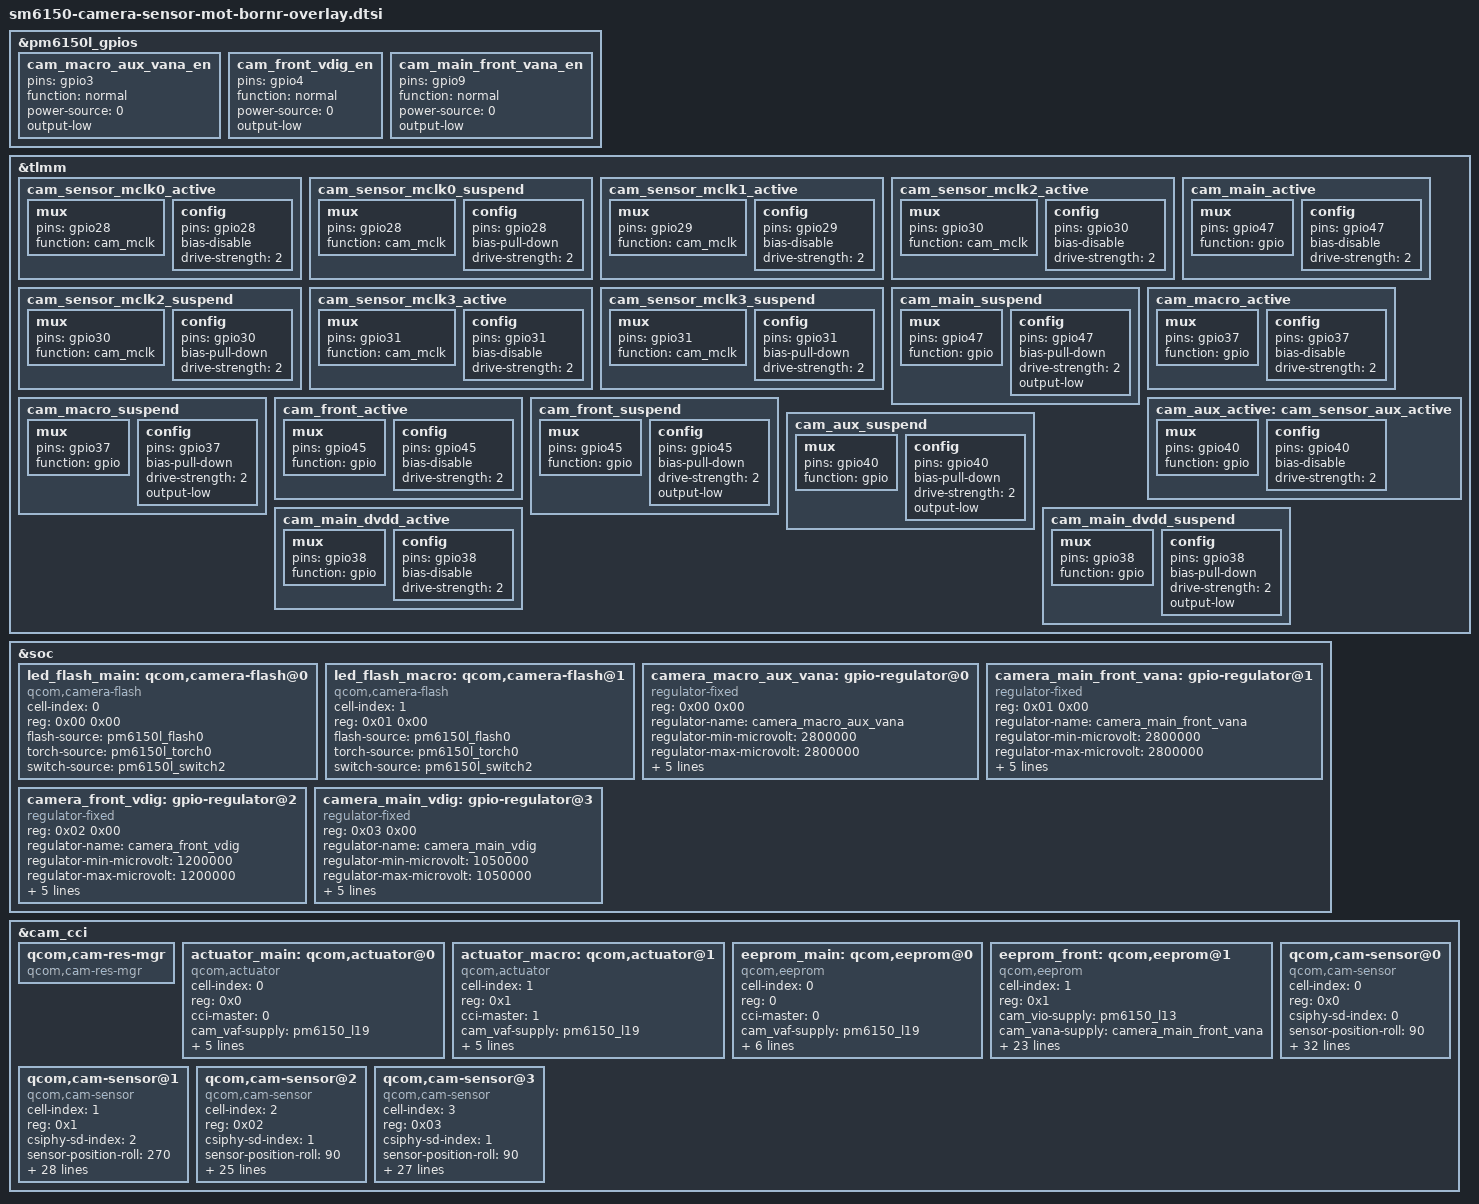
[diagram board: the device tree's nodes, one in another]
/*
 * Copyright (c) 2020, The Linux Foundation. All rights reserved.
 *
 * This program is free software; you can redistribute it and/or modify
 * it under the terms of the GNU General Public License version 2 and
 * only version 2 as published by the Free Software Foundation.
 *
 * This program is distributed in the hope that it will be useful,
 * but WITHOUT ANY WARRANTY; without even the implied warranty of
 * MERCHANTABILITY or FITNESS FOR A PARTICULAR PURPOSE.  See the
 * GNU General Public License for more details.
 */
&pm6150l_gpios {
	cam_macro_aux_vana_en: cam_macro_aux_vana_en {
		pins = "gpio3";
		function = "normal";
		power-source = <0>;
		output-low;
	};
	cam_front_vdig_en: cam_front_vdig_en {
		pins = "gpio4";
		function = "normal";
		power-source = <0>;
		output-low;
	};
	cam_main_front_vana_en: cam_main_front_vana_en {
		pins = "gpio9";
		function = "normal";
		power-source = <0>;
		output-low;
	};
};

&tlmm {
	cam_sensor_mclk0_active: cam_sensor_mclk0_active {
		/* MCLK0 */
		mux {
			pins = "gpio28";
			function = "cam_mclk";
		};

		config {
			pins = "gpio28";
			bias-disable; /* No PULL */
			drive-strength = <2>; /* 2 MA */
		};
	};

	cam_sensor_mclk0_suspend: cam_sensor_mclk0_suspend {
		/* MCLK0 */
		mux {
			pins = "gpio28";
			function = "cam_mclk";
		};

		config {
			pins = "gpio28";
			bias-pull-down; /* PULL DOWN */
			drive-strength = <2>; /* 2 MA */
		};
	};

	cam_sensor_mclk1_active: cam_sensor_mclk1_active {
		/* MCLK1 */
		mux {
			pins = "gpio29";
			function = "cam_mclk";
		};

		config {
			pins = "gpio29";
			bias-disable; /* No PULL */
			drive-strength = <2>; /* 2 MA */
		};
	};

	cam_sensor_mclk2_active: cam_sensor_mclk2_active {
		/* MCLK2 */
		mux {
			pins = "gpio30";
			function = "cam_mclk";
		};

		config {
			pins = "gpio30";
			bias-disable; /* No PULL */
			drive-strength = <2>; /* 2 MA */
		};
	};

	cam_sensor_mclk2_suspend: cam_sensor_mclk2_suspend {
		/* MCLK2 */
		mux {
			pins = "gpio30";
			function = "cam_mclk";
		};

		config {
			pins = "gpio30";
			bias-pull-down; /* PULL DOWN */
			drive-strength = <2>; /* 2 MA */
		};
	};

	cam_sensor_mclk3_active: cam_sensor_mclk3_active {
		/* MCLK3 */
		mux {
			pins = "gpio31";
			function = "cam_mclk";
		};

		config {
			pins = "gpio31";
			bias-disable; /* No PULL */
			drive-strength = <2>; /* 2 MA */
		};
	};

	cam_sensor_mclk3_suspend: cam_sensor_mclk3_suspend {
		/* MCLK3 */
		mux {
			pins = "gpio31";
			function = "cam_mclk";
		};

		config {
			pins = "gpio31";
			bias-pull-down; /* PULL DOWN */
			drive-strength = <2>; /* 2 MA */
		};
	};

	cam_main_active: cam_main_active {
		/* MAIN RESET */
		mux {
			pins = "gpio47";
			function = "gpio";
		};

		config {
			pins = "gpio47";
			bias-disable; /* No PULL */
			drive-strength = <2>; /* 2 MA */
		};
	};

	cam_main_suspend: cam_main_suspend {
		/* MAIN RESET */
		mux {
			pins = "gpio47";
			function = "gpio";
		};

		config {
			pins = "gpio47";
			bias-pull-down; /* PULL DOWN */
			drive-strength = <2>; /* 2 MA */
			output-low;
		};
	};

	cam_macro_active: cam_macro_active {
		/* MACRO RESET  */
		mux {
			pins = "gpio37";
			function = "gpio";
		};

		config {
			pins = "gpio37";
			bias-disable; /* No PULL */
			drive-strength = <2>; /* 2 MA */
		};
	};

	cam_macro_suspend: cam_macro_suspend {
		/* MACRO RESET */
		mux {
			pins = "gpio37";
			function = "gpio";
		};

		config {
			pins = "gpio37";
			bias-pull-down; /* PULL DOWN */
			drive-strength = <2>; /* 2 MA */
			output-low;
		};
	};

	cam_front_active: cam_front_active {
		/* FRONT RESET */
		mux {
			pins = "gpio45";
			function = "gpio";
		};

		config {
			pins = "gpio45";
			bias-disable; /* No PULL */
			drive-strength = <2>; /* 2 MA */
		};
	};

	cam_front_suspend: cam_front_suspend {
		/* FRONT RESET */
		mux {
			pins = "gpio45";
			function = "gpio";
		};

		config {
			pins = "gpio45";
			bias-pull-down; /* PULL DOWN */
			drive-strength = <2>; /* 2 MA */
			output-low;
		};
	};

	cam_aux_active: cam_sensor_aux_active {
		/* DEPTH RESET */
		mux {
			pins = "gpio40";
			function = "gpio";
		};

		config {
			pins = "gpio40";
			bias-disable; /* No PULL */
			drive-strength = <2>; /* 2 MA */
		};
	};

	cam_aux_suspend: cam_aux_suspend {
		/* DEPTH RESET */
		mux {
			pins = "gpio40";
			function = "gpio";
		};

		config {
			pins = "gpio40";
			bias-pull-down; /* PULL DOWN */
			drive-strength = <2>; /* 2 MA */
			output-low;
		};
	};

	cam_main_dvdd_active: cam_main_dvdd_active {
		/* MAIN DVDD EN */
		mux {
			pins = "gpio38";
			function = "gpio";
		};

		config {
			pins = "gpio38";
			bias-disable; /* No PULL */
			drive-strength = <2>; /* 2 MA */
		};
	};

	cam_main_dvdd_suspend: cam_main_dvdd_suspend {
		/* MAIN DVDD EN */
		mux {
			pins = "gpio38";
			function = "gpio";
		};

		config {
			pins = "gpio38";
			bias-pull-down; /* PULL DOWN */
			drive-strength = <2>; /* 2 MA */
			output-low;
		};
	};
};

&soc {

	led_flash_main: qcom,camera-flash@0 {
		cell-index = <0>;
		reg = <0x00 0x00>;
		compatible = "qcom,camera-flash";
		flash-source = <&pm6150l_flash0>;
		torch-source = <&pm6150l_torch0>;
		switch-source = <&pm6150l_switch2>;
		status = "ok";
	};

	led_flash_macro: qcom,camera-flash@1 {
		cell-index = <1>;
		reg = <0x01 0x00>;
		compatible = "qcom,camera-flash";
		flash-source = <&pm6150l_flash0>;
		torch-source = <&pm6150l_torch0>;
		switch-source = <&pm6150l_switch2>;
		status = "ok";
	};

	camera_macro_aux_vana: gpio-regulator@0 {
		compatible = "regulator-fixed";
		reg = <0x00 0x00>;
		regulator-name = "camera_macro_aux_vana";
		regulator-min-microvolt = <2800000>;
		regulator-max-microvolt = <2800000>;
		regulator-enable-ramp-delay = <135>;
		enable-active-high;
		gpio = <&pm6150l_gpios 3 0>;
		pinctrl-names = "default";
		pinctrl-0 = <&cam_macro_aux_vana_en>;
		vin-supply = <&pm6150l_bob>;
	};

	camera_main_front_vana: gpio-regulator@1 {
		compatible = "regulator-fixed";
		reg = <0x01 0x00>;
		regulator-name = "camera_main_front_vana";
		regulator-min-microvolt = <2800000>;
		regulator-max-microvolt = <2800000>;
		regulator-enable-ramp-delay = <233>;
		enable-active-high;
		gpio = <&pm6150l_gpios 9 0>;
		pinctrl-names = "default";
		pinctrl-0 = <&cam_main_front_vana_en>;
		vin-supply = <&pm6150l_bob>;
	};

	camera_front_vdig: gpio-regulator@2 {
		compatible = "regulator-fixed";
		reg = <0x02 0x00>;
		regulator-name = "camera_front_vdig";
		regulator-min-microvolt = <1200000>;
		regulator-max-microvolt = <1200000>;
		regulator-enable-ramp-delay = <233>;
		enable-active-high;
		gpio = <&pm6150l_gpios 4 0>;
		pinctrl-names = "default";
		pinctrl-0 = <&cam_front_vdig_en>;
		vin-supply = <&pm6150l_s8>;
	};

	camera_main_vdig: gpio-regulator@3 {
		compatible = "regulator-fixed";
		reg = <0x03 0x00>;
		regulator-name = "camera_main_vdig";
		regulator-min-microvolt = <1050000>;
		regulator-max-microvolt = <1050000>;
		regulator-enable-ramp-delay = <135>;
		enable-active-high;
		gpio = <&tlmm 38 0>;
		pinctrl-names = "default";
		pinctrl-0 = <&cam_main_dvdd_active>;
		vin-supply = <&pm6150l_s8>;
	};
};

&cam_cci {
	qcom,cam-res-mgr {
		compatible = "qcom,cam-res-mgr";
		status = "ok";
	};

	actuator_main: qcom,actuator@0 {
		cell-index = <0>;
		reg = <0x0>;
		compatible = "qcom,actuator";
		cci-master = <0>;
		cam_vaf-supply = <&pm6150_l19>;
		regulator-names = "cam_vaf";
		rgltr-cntrl-support;
		rgltr-min-voltage = <2800000>;
		rgltr-max-voltage = <2800000>;
		rgltr-load-current = <100000>;
	};

	actuator_macro: qcom,actuator@1 {
		cell-index = <1>;
		reg = <0x1>;
		compatible = "qcom,actuator";
		cci-master = <1>;
		cam_vaf-supply = <&pm6150_l19>;
		regulator-names = "cam_vaf";
		rgltr-cntrl-support;
		rgltr-min-voltage = <2800000>;
		rgltr-max-voltage = <2800000>;
		rgltr-load-current = <100000>;
	};

	eeprom_main: qcom,eeprom@0 {
		cell-index = <0>;
		reg = <0>;
		compatible = "qcom,eeprom";
		cci-master = <0>;
		cam_vaf-supply = <&pm6150_l19>;
		cam_vio-supply = <&pm6150_l13>;
		regulator-names = "cam_vaf", "cam_vio";
		rgltr-cntrl-support;
		rgltr-min-voltage = <2800000 1800000>;
		rgltr-max-voltage = <2800000 1800000>;
		rgltr-load-current = <100000 120000>;
		status = "ok";
	};

	eeprom_front: qcom,eeprom@1 {
		cell-index = <1>;
		compatible = "qcom,eeprom";
		reg = <0x1>;
		cam_vio-supply = <&pm6150_l13>;
		cam_vana-supply = <&camera_main_front_vana>;
		cam_vdig-supply = <&camera_front_vdig>;
		cam_clk-supply = <&titan_top_gdsc>;
		regulator-names = "cam_vio", "cam_vana", "cam_vdig",
			"cam_clk";
		rgltr-cntrl-support;
		rgltr-min-voltage = <1800000 2800000 1200000 0>;
		rgltr-max-voltage = <1800000 2800000 1200000 0>;
		rgltr-load-current = <0 80000 105000 0>;
		gpio-no-mux = <0>;
		pinctrl-names = "cam_default", "cam_suspend";
		pinctrl-0 = <&cam_sensor_mclk1_active
				&cam_front_active>;
		pinctrl-1 = <&cam_sensor_mclk1_suspend
				&cam_front_suspend>;
		gpios = <&tlmm 29 0>,
			<&tlmm 45 0>;
		gpio-reset = <1>;
		gpio-req-tbl-num = <0 1>;
		gpio-req-tbl-flags = <1 0>;
		gpio-req-tbl-label = "CAMIF_MCLK1",
					"CAM_RESET1";
		sensor-mode = <0>;
		cci-master = <0>;
		status = "ok";
		clocks = <&clock_camcc CAM_CC_MCLK1_CLK>;
		clock-names = "cam_clk";
		clock-cntl-level = "turbo";
		clock-rates = <24000000>;
	};

	qcom,cam-sensor@0 {
		cell-index = <0>;
		compatible = "qcom,cam-sensor";
		reg = <0x0>;
		csiphy-sd-index = <0>;
		sensor-position-roll = <90>;
		sensor-position-pitch = <0>;
		sensor-position-yaw = <180>;
		actuator-src = <&actuator_main>;
		eeprom-src = <&eeprom_main>;
		led-flash-src = <&led_flash_main>;
		cam_vio-supply = <&pm6150_l13>;
		cam_vana-supply = <&camera_main_front_vana>;
		cam_vdig-supply = <&camera_main_vdig>;
		cam_clk-supply = <&titan_top_gdsc>;
		regulator-names = "cam_vio", "cam_vana", "cam_vdig",
			"cam_clk";
		rgltr-cntrl-support;
		rgltr-min-voltage = <1800000 2800000 1050000 0>;
		rgltr-max-voltage = <1800000 2800000 1050000 0>;
		rgltr-load-current = <0 80000 105000 0>;
		gpio-no-mux = <0>;
		pinctrl-names = "cam_default", "cam_suspend";
		pinctrl-0 = <&cam_sensor_mclk0_active
				&cam_main_active
				&cam_front_active>;
		pinctrl-1 = <&cam_sensor_mclk0_suspend
				&cam_main_suspend
				&cam_front_suspend>;
		gpios = <&tlmm 28 0>,
			<&tlmm 47 0>,
			<&tlmm 45 0>;
		gpio-reset = <1>;
		gpio-standby = <2>;
		gpio-req-tbl-num = <0 1 2>;
		gpio-req-tbl-flags = <1 0 0>;
		gpio-req-tbl-label = "CAMIF_MCLK0",
					"CAM_RESET0",
					"CAM_STANDBY0";
		sensor-mode = <0>;
		cci-master = <0>;
		status = "ok";
		clocks = <&clock_camcc CAM_CC_MCLK0_CLK>;
		clock-names = "cam_clk";
		clock-cntl-level = "turbo";
		clock-rates = <24000000>;
	};

	qcom,cam-sensor@1 {
		cell-index = <1>;
		compatible = "qcom,cam-sensor";
		reg = <0x1>;
		csiphy-sd-index = <2>;
		sensor-position-roll = <270>;
		sensor-position-pitch = <0>;
		sensor-position-yaw = <180>;
		eeprom-src = <&eeprom_front>;
		cam_vio-supply = <&pm6150_l13>;
		cam_vana-supply = <&camera_main_front_vana>;
		cam_vdig-supply = <&camera_front_vdig>;
		cam_clk-supply = <&titan_top_gdsc>;
		regulator-names = "cam_vio", "cam_vana", "cam_vdig",
			"cam_clk";
		rgltr-cntrl-support;
		rgltr-min-voltage = <1800000 2800000 1200000 0>;
		rgltr-max-voltage = <1800000 2800000 1200000 0>;
		rgltr-load-current = <0 80000 105000 0>;
		gpio-no-mux = <0>;
		pinctrl-names = "cam_default", "cam_suspend";
		pinctrl-0 = <&cam_sensor_mclk1_active
				&cam_front_active>;
		pinctrl-1 = <&cam_sensor_mclk1_suspend
				&cam_front_suspend>;
		gpios = <&tlmm 29 0>,
			<&tlmm 45 0>;
		gpio-reset = <1>;
		gpio-req-tbl-num = <0 1>;
		gpio-req-tbl-flags = <1 0>;
		gpio-req-tbl-label = "CAMIF_MCLK1",
					"CAM_RESET1";
		sensor-mode = <0>;
		cci-master = <0>;
		status = "ok";
		clocks = <&clock_camcc CAM_CC_MCLK1_CLK>;
		clock-names = "cam_clk";
		clock-cntl-level = "turbo";
		clock-rates = <24000000>;
	};

	qcom,cam-sensor@2 {
		cell-index = <2>;
		compatible = "qcom,cam-sensor";
		reg = <0x02>;
		csiphy-sd-index = <1>;
		sensor-position-roll = <90>;
		sensor-position-pitch = <0>;
		sensor-position-yaw = <180>;
		cam_vio-supply = <&pm6150_l13>;
		cam_vana-supply = <&camera_macro_aux_vana>;
		cam_clk-supply = <&titan_top_gdsc>;
		regulator-names = "cam_vio", "cam_vana", "cam_clk";
		rgltr-cntrl-support;
		rgltr-min-voltage = <1800000 2800000 0>;
		rgltr-max-voltage = <1800000 2800000 0>;
		rgltr-load-current = <0 80000 0>;
		gpio-no-mux = <0>;
		pinctrl-names = "cam_default", "cam_suspend";
		pinctrl-0 = <&cam_sensor_mclk3_active
				 &cam_aux_active>;
		pinctrl-1 = <&cam_sensor_mclk3_suspend
				 &cam_aux_suspend>;
		gpios = <&tlmm 31 0>,
			<&tlmm 40 0>;
		gpio-reset = <1>;
		gpio-req-tbl-num = <0 1>;
		gpio-req-tbl-flags = <1 0>;
		gpio-req-tbl-label = "CAMIF_MCLK3",
					"CAM_RESET2";
		sensor-mode = <0>;
		cci-master = <1>;
		status = "ok";
		clocks = <&clock_camcc CAM_CC_MCLK3_CLK>;
		clock-names = "cam_clk";
		clock-cntl-level = "turbo";
		clock-rates = <24000000>;
	};

	qcom,cam-sensor@3 {
		cell-index = <3>;
		compatible = "qcom,cam-sensor";
		reg = <0x03>;
		csiphy-sd-index = <1>;
		sensor-position-roll = <90>;
		sensor-position-pitch = <0>;
		sensor-position-yaw = <180>;
		actuator-src = <&actuator_macro>;
		led-flash-src = <&led_flash_macro>;
		cam_vio-supply = <&pm6150_l13>;
		cam_vana-supply = <&camera_macro_aux_vana>;
		cam_clk-supply = <&titan_top_gdsc>;
		regulator-names = "cam_vio", "cam_vana", "cam_clk";
		rgltr-cntrl-support;
		rgltr-min-voltage = <1800000 2800000 0>;
		rgltr-max-voltage = <1800000 2800000 0>;
		rgltr-load-current = <0 80000 0>;
		gpio-no-mux = <0>;
		pinctrl-names = "cam_default", "cam_suspend";
		pinctrl-0 = <&cam_sensor_mclk2_active
				 &cam_macro_active>;
		pinctrl-1 = <&cam_sensor_mclk2_suspend
				 &cam_macro_suspend>;
		gpios = <&tlmm 30 0>,
			<&tlmm 37 0>;
		gpio-reset = <1>;
		gpio-req-tbl-num = <0 1>;
		gpio-req-tbl-flags = <1 0>;
		gpio-req-tbl-label = "CAMIF_MCLK2",
					"CAM_RESET3";
		sensor-mode = <0>;
		cci-master = <1>;
		status = "ok";
		clocks = <&clock_camcc CAM_CC_MCLK2_CLK>;
		clock-names = "cam_clk";
		clock-cntl-level = "turbo";
		clock-rates = <24000000>;
	};
};
